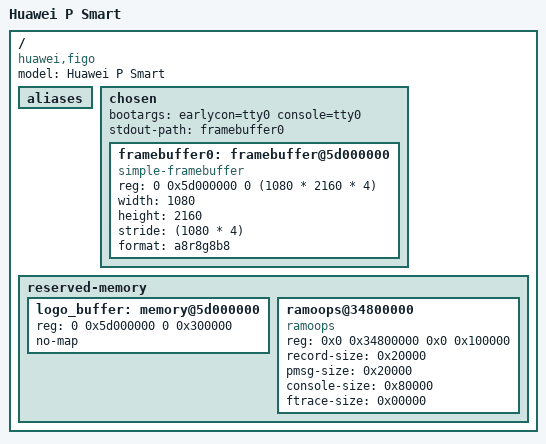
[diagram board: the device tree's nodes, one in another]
/dts-v1/;

#include "hi6250.dtsi"

/ {
	model = "Huawei P Smart";
	compatible = "huawei,figo", "hisilicon,hi6250";
    
	aliases {};

	chosen {
		bootargs = "earlycon=tty0 console=tty0";

		#address-cells = <2>;
		#size-cells = <2>;
		ranges;

		stdout-path = "framebuffer0";

		framebuffer0: framebuffer@5d000000 {
			compatible = "simple-framebuffer";
			reg = <0 0x5d000000 0 (1080 * 2160 * 4)>;
			width = <1080>;
			height = <2160>;
			stride = <(1080 * 4)>;
			format = "a8r8g8b8";
			status = "okay";
		};
	};

	reserved-memory {
		logo_buffer: memory@5d000000 {
			reg = <0 0x5d000000 0 0x300000>;
			no-map;
		};

		ramoops@34800000 {
			compatible = "ramoops";
			reg = <0x0 0x34800000 0x0 0x100000>;
			record-size = <0x20000>;
			pmsg-size = <0x20000>;
			console-size = <0x80000>;
			ftrace-size = <0x00000>;
		};  
	};
};
